AUTOSAR XML (schema 4-2-1)
package /ComponentTypes
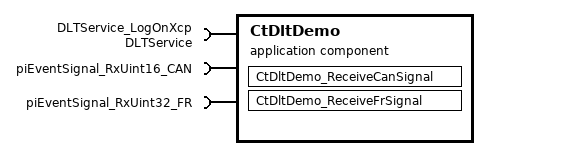
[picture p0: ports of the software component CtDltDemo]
  application sw component type CtDltDemo
    require port DLTService_LogOnXcp: required-interface=DLTService
    require port piEventSignal_RxUint16_CAN: nonqueued-receiver-com-spec{data-element=deEventSignal_RxUint16_CAN, filter=data-filter-type=ALWAYS, init-value=25}, required-interface=piEventSignal_RxUint16_CAN
    require port piEventSignal_RxUint32_FR: nonqueued-receiver-com-spec{data-element=deEventSignal_RxUint32_FR, filter=data-filter-type=ALWAYS, init-value=1}, required-interface=piEventSignal_RxUint32_FR
    behavior CtDltDemo_InternalBehavior
      data received event DRT_CtDltDemo_ReceiveCanSignal_piEventSignal_RxUint16_CAN_deEventSignal_RxUint16_CAN: start-on-event=CtDltDemo_ReceiveCanSignal, data=piEventSignal_RxUint16_CAN.deEventSignal_RxUint16_CAN
      data received event DRT_CtDltDemo_ReceiveFrSignal_piEventSignal_RxUint32_FR_deEventSignal_RxUint32_FR: start-on-event=CtDltDemo_ReceiveFrSignal, data=piEventSignal_RxUint32_FR.deEventSignal_RxUint32_FR
      runnable CtDltDemo_ReceiveCanSignal
        data-receive-point-by-arguments:
          access REC_piEventSignal_RxUint16_CAN_deEventSignal_RxUint16_CAN: accessed-variable=piEventSignal_RxUint16_CAN.deEventSignal_RxUint16_CAN
        sync call SC_DLTService_LogOnXcp_SendLogMessage: operation=DLTService_LogOnXcp.SendLogMessage, timeout=0
      runnable CtDltDemo_ReceiveFrSignal
        data-receive-point-by-arguments:
          access REC_piEventSignal_RxUint32_FR_deEventSignal_RxUint32_FR: accessed-variable=piEventSignal_RxUint32_FR.deEventSignal_RxUint32_FR
        sync call SC_DLTService_LogOnXcp_SendLogMessage: operation=DLTService_LogOnXcp.SendLogMessage, timeout=0
  swc implementation CtDltDemo_Implementation: behavior=CtDltDemo_InternalBehavior
    code-descriptors:
      code Default: artifact-descriptors=autosar-engineering-object={short-label=Default, category=SWSRC}
